# STM32F303C6T6 register map
File version: 1.0
Registers are 32-bit, access not given, reset 0x0 unless marked. A register's access mark holds for its fields unless they carry their own. Offsets are from the block's base; [hi:lo] are bit positions; {n}, {i} and the like mark numbered series.

## EXTI
Base 0x40010400
0x00 IMR1
  [31:0] MR
0x04 EMR1
  [31:0] MR
0x08 RTSR1
  [28:23] s, [31:0] TR
0x0C FTSR1
  [28:23] s, [31:0] TR
0x10 SWIER1
  [28:23] s, [31:0] SWIER
0x14 PR1
  [28:23] s, [31:0] PR
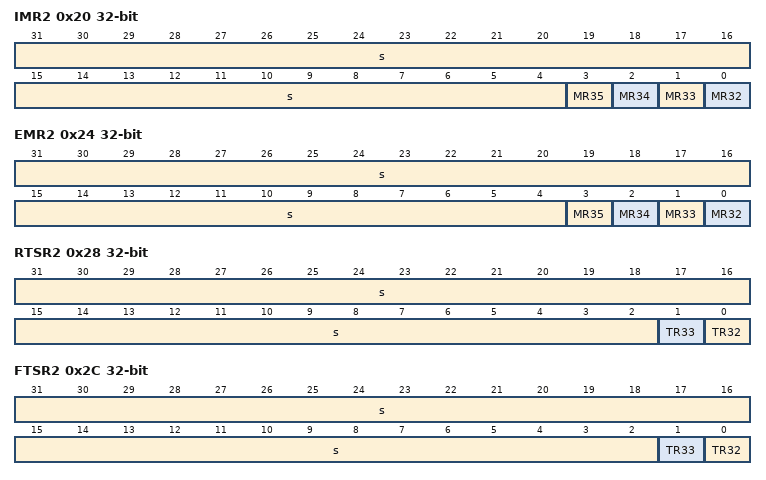
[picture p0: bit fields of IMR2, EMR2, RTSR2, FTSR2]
0x20 IMR2
  [31:4] s, [n-32] MR{n} (n=32..35)
0x24 EMR2
  [31:4] s, [n-32] MR{n} (n=32..35)
0x28 RTSR2
  [31:2] s, [1] TR33, [0] TR32
0x2C FTSR2
  [31:2] s, [1] TR33, [0] TR32
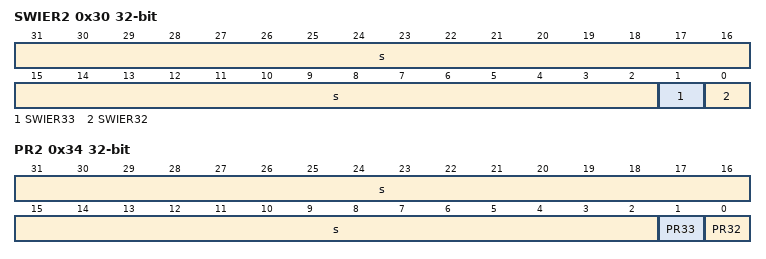
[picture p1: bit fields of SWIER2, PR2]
0x30 SWIER2
  [31:2] s, [1] SWIER33, [0] SWIER32
0x34 PR2
  [31:2] s, [1] PR33, [0] PR32

## TIM1
Base 0x40012C00
0x00 CR1
  [11] UIFREMAP, [31:10] s, [9:8] CKD, [7] ARPE, [6:5] CMS, [4] DIR, [3] OPM, [2] URS, [1] UDIS, [0] CEN
0x04 CR2
  [23:20] MMS2, [2n+6] OIS{n} (n=1..6), [13] OIS3N, [11] OIS2N, [9] OIS1N, [7] TI1S, [6:4] MMS, [3] CCDS, [2] CCUS, [31:1] s, [0] CCPC
0x08 SMCR
  [31:17] s, [15] ETP, [14] ECE, [13:12] ETPS, [11:8] ETF, [7] MSM, [6:4] TS, [3] OCCS, [16:0] SMS
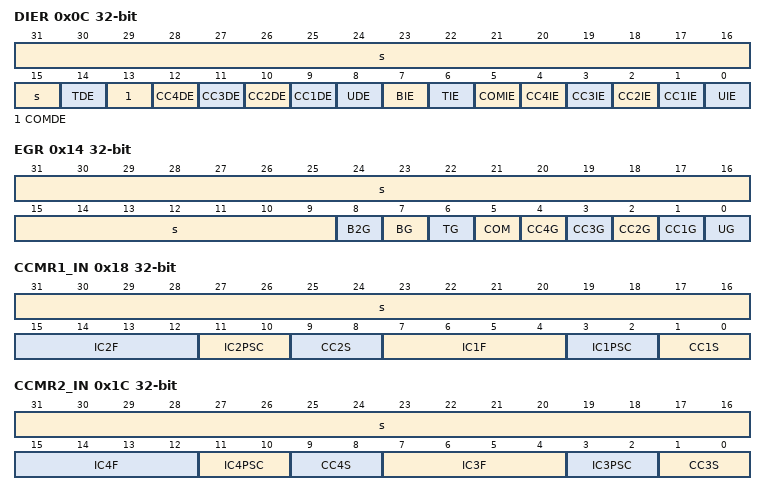
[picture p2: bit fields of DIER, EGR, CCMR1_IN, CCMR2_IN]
0x0C DIER
  [31:15] s, [14] TDE, [13] COMDE, [n+8] CC{n}DE (n=1..4), [8] UDE, [7] BIE, [6] TIE, [5] COMIE, [n] CC{n}IE (n=1..4), [0] UIE
0x10 SR
  [17] CC6IF, [16] CC5IF, [31:13] s, [n+8] CC{n}OF (n=1..4), [8] B2IF, [7] BIF, [6] TIF, [5] COMIF, [n] CC{n}IF (n=1..4), [0] UIF
0x14 EGR
  [31:9] s, [8] B2G, [7] BG, [6] TG, [5] COM, [n] CC{n}G (n=1..4), [0] UG
0x18 CCMR1_OUT
  [31:17] s, [15] OC2CE, [24:12] OC2M, [11] OC2PE, [10] OC2FE, [9:8] CC2S, [7] OC1CE, [16:4] OC1M, [3] OC1PE, [2] OC1FE, [1:0] CC1S
0x18 CCMR1_IN
  [31:16] s, [15:12] IC2F, [11:10] IC2PSC, [9:8] CC2S, [7:4] IC1F, [3:2] IC1PSC, [1:0] CC1S
0x1C CCMR2_OUT
  [31:17] s, [15] OC4CE, [24:12] OC4M, [11] OC4PE, [10] OC4FE, [9:8] CC4S, [7] OC3CE, [16:4] OC3M, [3] OC3PE, [2] OC3FE, [1:0] CC3S
0x1C CCMR2_IN
  [31:16] s, [15:12] IC4F, [11:10] IC4PSC, [9:8] CC4S, [7:4] IC3F, [3:2] IC3PSC, [1:0] CC3S
0x20 CCER
  [4n-3] CC{n}P (n=1..6), [4n-4] CC{n}E (n=1..6), [31:14] s, [11] CC3NP, [10] CC3NE, [7] CC2NP, [6] CC2NE, [3] CC1NP, [2] CC1NE
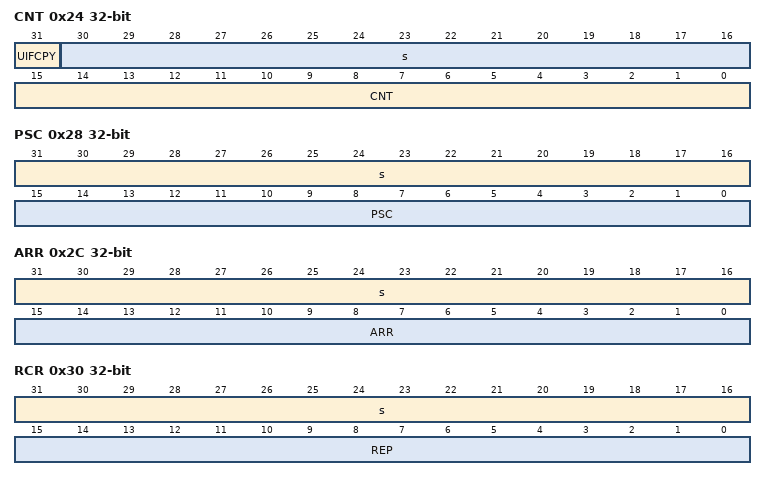
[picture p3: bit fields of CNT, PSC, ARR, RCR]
0x24 CNT
  [31] UIFCPY, [30:16] s, [15:0] CNT
0x28 PSC
  [31:16] s, [15:0] PSC
0x2C ARR
  [31:16] s, [15:0] ARR
0x30 RCR
  [31:16] s, [15:0] REP
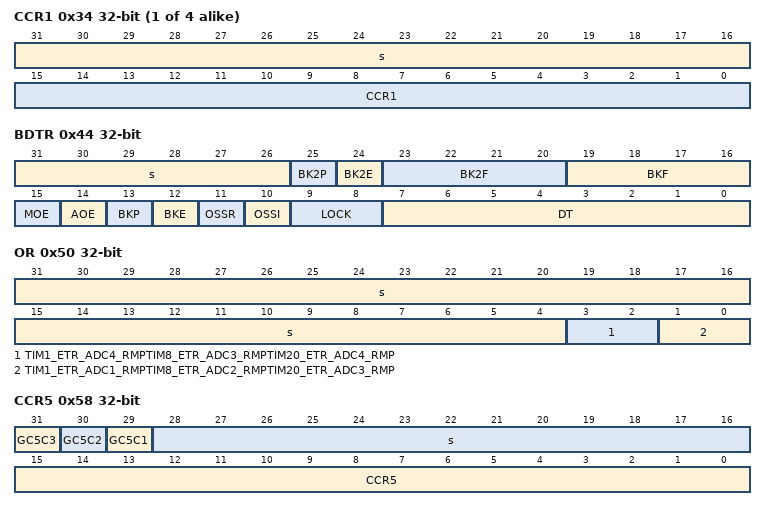
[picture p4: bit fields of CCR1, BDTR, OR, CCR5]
{0x30+4i} CCR{i} (i=1..4)
  [31:16] s, [15:0] CCR{i}
0x44 BDTR
  [31:26] s, [25] BK2P, [24] BK2E, [23:20] BK2F, [19:16] BKF, [15] MOE, [14] AOE, [13] BKP, [12] BKE, [11] OSSR, [10] OSSI, [9:8] LOCK, [7:0] DT
0x48 DCR
  [12:8] DBL, [31:5] s, [4:0] DBA
0x4C DMAR
  [31:0] DMAB
0x50 OR
  [31:4] s, [3:2] TIM1_ETR_ADC4_RMPTIM8_ETR_ADC3_RMPTIM20_ETR_ADC4_RMP, [1:0] TIM1_ETR_ADC1_RMPTIM8_ETR_ADC2_RMPTIM20_ETR_ADC3_RMP
0x54 CCMR3_OUT
  [15] OC6CE, [24:12] OC6M, [11] OC6PE, [10] OC6FE, [7] OC5CE, [16:4] OC5M, [3] OC5PE, [2] OC5FE, [31:0] s
0x58 CCR5
  [31] GC5C3, [30] GC5C2, [29] GC5C1, [28:16] s, [15:0] CCR5
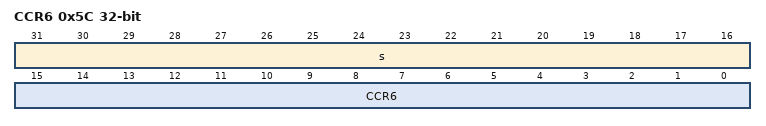
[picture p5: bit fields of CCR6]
0x5C CCR6
  [31:16] s, [15:0] CCR6

## SPI1
Base 0x40013000
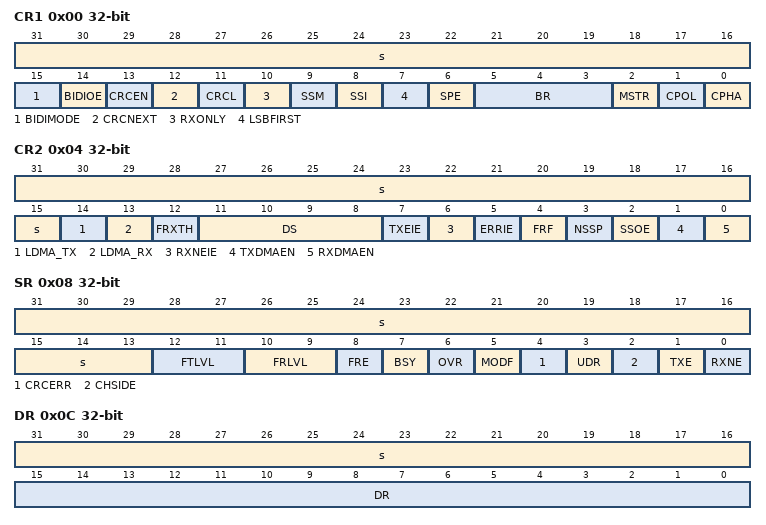
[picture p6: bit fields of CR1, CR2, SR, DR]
0x00 CR1
  [31:16] s, [15] BIDIMODE, [14] BIDIOE, [13] CRCEN, [12] CRCNEXT, [11] CRCL, [10] RXONLY, [9] SSM, [8] SSI, [7] LSBFIRST, [6] SPE, [5:3] BR, [2] MSTR, [1] CPOL, [0] CPHA
0x04 CR2
  [31:15] s, [14] LDMA_TX, [13] LDMA_RX, [12] FRXTH, [11:8] DS, [7] TXEIE, [6] RXNEIE, [5] ERRIE, [4] FRF, [3] NSSP, [2] SSOE, [1] TXDMAEN, [0] RXDMAEN
0x08 SR
  [31:13] s, [12:11] FTLVL, [10:9] FRLVL, [8] FRE, [7] BSY, [6] OVR, [5] MODF, [4] CRCERR, [3] UDR, [2] CHSIDE, [1] TXE, [0] RXNE
0x0C DR
  [31:16] s, [15:0] DR
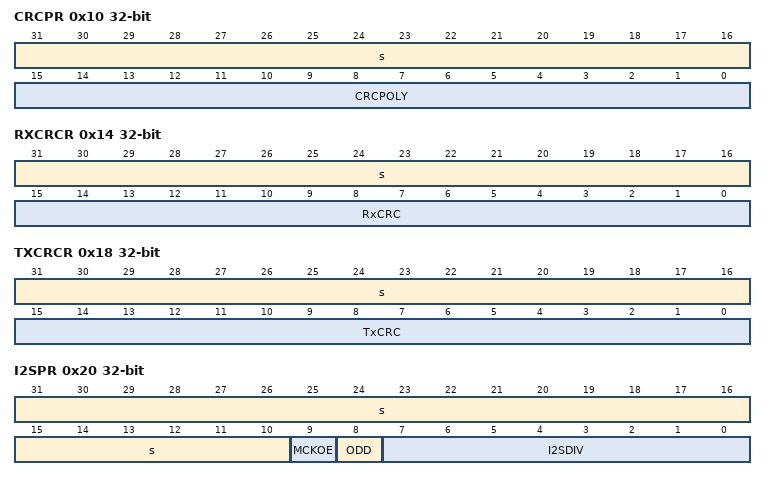
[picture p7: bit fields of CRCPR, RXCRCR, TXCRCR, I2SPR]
0x10 CRCPR
  [31:16] s, [15:0] CRCPOLY
0x14 RXCRCR
  [31:16] s, [15:0] RxCRC
0x18 TXCRCR
  [31:16] s, [15:0] TxCRC
0x1C I2SCFGR
  [11] I2SMOD, [10] I2SE, [9:8] I2SCFG, [7] PCMSYNC, [31:6] s, [5:4] I2SSTD, [3] CKPOL, [2:1] DATLEN, [0] CHLEN
0x20 I2SPR
  [31:10] s, [9] MCKOE, [8] ODD, [7:0] I2SDIV

## TIM15
Base 0x40014000
0x00 CR1
  [11] UIFREMAP, [9:8] CKD, [7] ARPE, [31:4] s, [3] OPM, [2] URS, [1] UDIS, [0] CEN
0x04 CR2
  [10] OIS2, [9] OIS1N, [8] OIS1, [7] TI1S, [6:4] MMS, [3] CCDS, [2] CCUS, [31:1] s, [0] CCPC
0x08 SMCR
  [7] MSM, [6:4] TS, [31:3] s, [16:0] SMS
0x0C DIER
  [14] TDE, [13] COMDE, [10] CC2DE, [9] CC1DE, [8] UDE, [7] BIE, [6] TIE, [5] COMIE, [31:3] s, [2] CC2IE, [1] CC1IE, [0] UIE
0x10 SR
  [10] CC2OF, [9] CC1OF, [7] BIF, [6] TIF, [5] COMIF, [31:3] s, [2] CC2IF, [1] CC1IF, [0] UIF
0x14 EGR
  [7] BG, [6] TG, [5] COMG, [31:3] s, [2] CC2G, [1] CC1G, [0] UG
0x18 CCMR1_OUT
  [31:15] s, [24:12] OC2M, [11] OC2PE, [10] OC2FE, [9:8] CC2S, [7] OC1CE, [16:4] OC1M, [3] OC1PE, [2] OC1FE, [1:0] CC1S
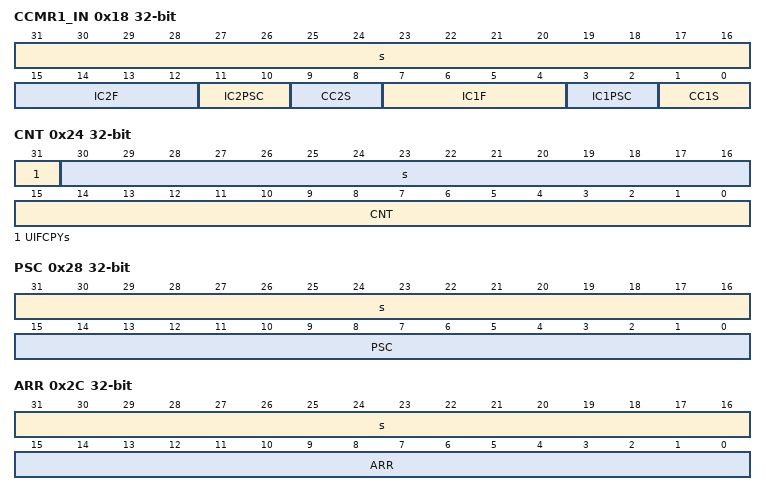
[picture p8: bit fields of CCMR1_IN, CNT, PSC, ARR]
0x18 CCMR1_IN
  [31:16] s, [15:12] IC2F, [11:10] IC2PSC, [9:8] CC2S, [7:4] IC1F, [3:2] IC1PSC, [1:0] CC1S
0x20 CCER
  [7] CC2NP, [31:6] s, [5] CC2P, [4] CC2E, [3] CC1NP, [2] CC1NE, [1] CC1P, [0] CC1E
0x24 CNT
  [31] UIFCPYs, [30:16] s, [15:0] CNT
0x28 PSC
  [31:16] s, [15:0] PSC
0x2C ARR
  [31:16] s, [15:0] ARR
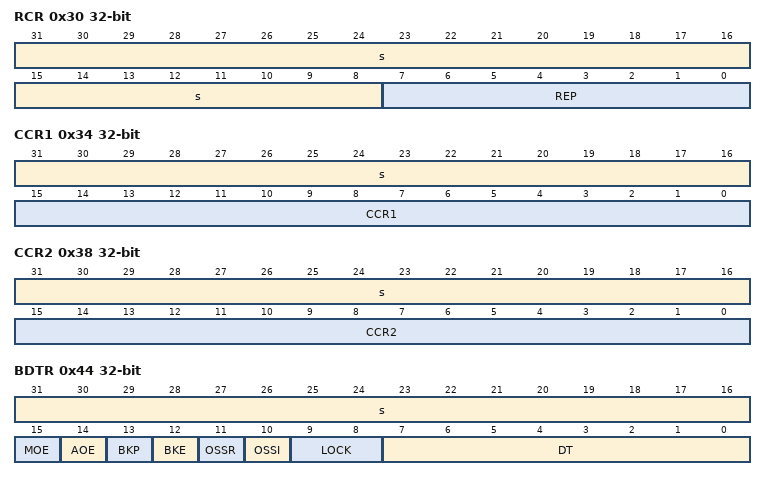
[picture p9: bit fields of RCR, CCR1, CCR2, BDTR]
0x30 RCR
  [31:8] s, [7:0] REP
0x34 CCR1
  [31:16] s, [15:0] CCR1
0x38 CCR2
  [31:16] s, [15:0] CCR2
0x44 BDTR
  [31:16] s, [15] MOE, [14] AOE, [13] BKP, [12] BKE, [11] OSSR, [10] OSSI, [9:8] LOCK, [7:0] DT
0x48 DCR
  [12:8] DBL, [31:5] s, [4:0] DBA
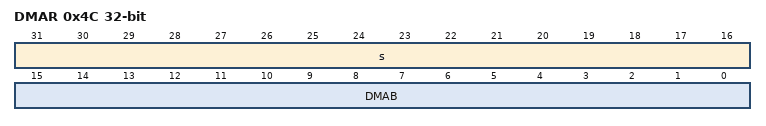
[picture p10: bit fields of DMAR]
0x4C DMAR
  [31:16] s, [15:0] DMAB
